VERSION ""

NS_ :

BS_:

BU_: BKU KVU
VAL_TABLE_ kvu_Workmodes 2 "Driver control" 1 "Local control from VMU commands" 0 "Controlled from BKU" ;
VAL_TABLE_ bku_lightsTurnMode 3 "Alarm" 2 "Right" 1 "Left" 0 "Disabled" ;
VAL_TABLE_ kvu_errorCode_priority 1 "critical" 0 "warning" ;
VAL_TABLE_ kvu_errorCode_source 17 "Power_management" 16 "Motor_drive" 15 "Voltage_monitoring" 14 "Suspension" 13 "Hydraulic_brakes" 12 "Charging" 11 "IO_lib_errors" 10 "Discrete_input" 9 "ABS" 8 "System" 7 "Parking_brake" 6 "Steering_rear" 5 "Steering_front" 4 "J1939" 3 "EEPROM" 2 "Lights" 1 "Canopen" 0 "Undefined" ;

BO_ 2566885541 BKU_resetErrors: 8 BKU
 SG_ bku_resetErrors_bits : 0|40@1+ (1,0) [0|1099511627775] ""  KVU

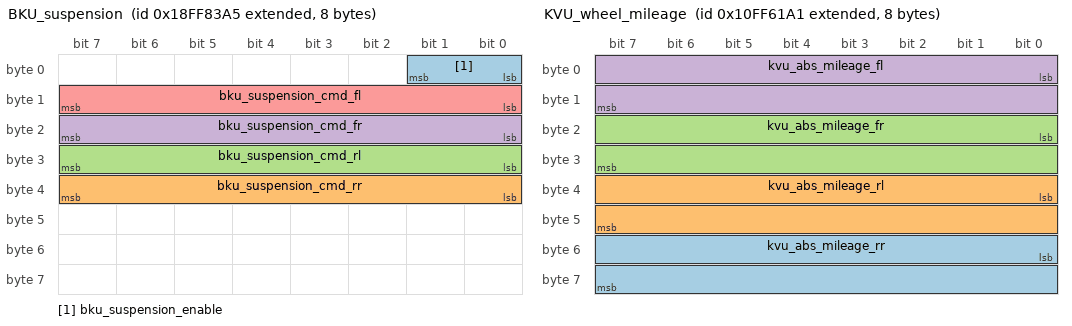
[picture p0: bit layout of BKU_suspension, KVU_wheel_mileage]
BO_ 2566882213 BKU_suspension: 8 BKU
 SG_ bku_suspension_enable : 0|2@1+ (1,0) [0|3] ""  KVU
 SG_ bku_suspension_cmd_rr : 32|8@1+ (2,-250) [-250|250] "mm"  KVU
 SG_ bku_suspension_cmd_rl : 24|8@1+ (2,-250) [-250|250] "mm"  KVU
 SG_ bku_suspension_cmd_fr : 16|8@1+ (2,-250) [-250|250] "mm"  KVU
 SG_ bku_suspension_cmd_fl : 8|8@1+ (2,-250) [-250|250] "mm"  KVU

BO_ 2432655777 KVU_wheel_mileage: 8 KVU
 SG_ kvu_abs_mileage_rr : 48|16@1+ (1,0) [0|32767] ""  BKU
 SG_ kvu_abs_mileage_rl : 32|16@1+ (1,0) [0|32767] ""  BKU
 SG_ kvu_abs_mileage_fr : 16|16@1+ (1,0) [0|32767] ""  BKU
 SG_ kvu_abs_mileage_fl : 0|16@1+ (1,0) [0|32767] ""  BKU

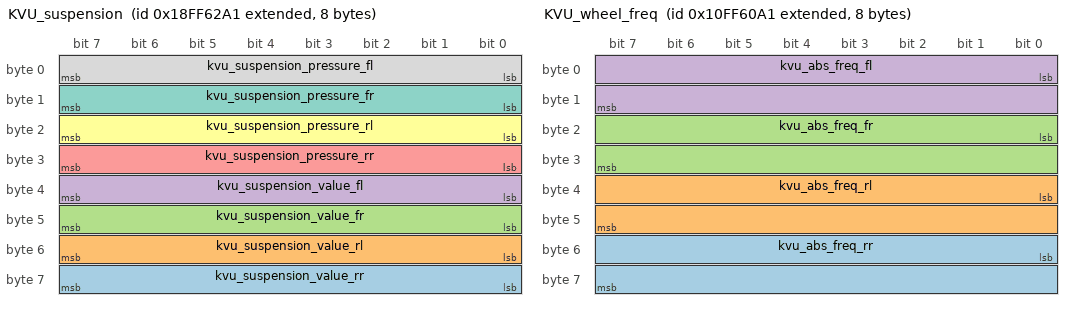
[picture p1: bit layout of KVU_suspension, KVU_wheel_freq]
BO_ 2566873761 KVU_suspension: 8 KVU
 SG_ kvu_suspension_value_rr : 56|8@1+ (2,-250) [-250|260] "mm"  BKU
 SG_ kvu_suspension_value_rl : 48|8@1+ (2,-250) [-250|260] "mm"  BKU
 SG_ kvu_suspension_value_fr : 40|8@1+ (2,-250) [-250|260] "mm"  BKU
 SG_ kvu_suspension_value_fl : 32|8@1+ (2,-250) [-250|260] "mm"  BKU
 SG_ kvu_suspension_pressure_rr : 24|8@1+ (0.1,0) [0|25] "atm"  BKU
 SG_ kvu_suspension_pressure_rl : 16|8@1+ (0.1,0) [0|25] "atm"  BKU
 SG_ kvu_suspension_pressure_fr : 8|8@1+ (0.1,0) [0|25] "atm"  BKU
 SG_ kvu_suspension_pressure_fl : 0|8@1+ (0.1,0) [0|25] "atm"  BKU

BO_ 2432655521 KVU_wheel_freq: 8 KVU
 SG_ kvu_abs_freq_rr : 48|16@1+ (0.002,-50) [-50|81.07] "Hz"  BKU
 SG_ kvu_abs_freq_rl : 32|16@1+ (0.002,-50) [-50|81.07] "Hz"  BKU
 SG_ kvu_abs_freq_fr : 16|16@1+ (0.002,-50) [-50|81.07] "Hz"  BKU
 SG_ kvu_abs_freq_fl : 0|16@1+ (0.002,-50) [-50|81.07] "Hz"  BKU

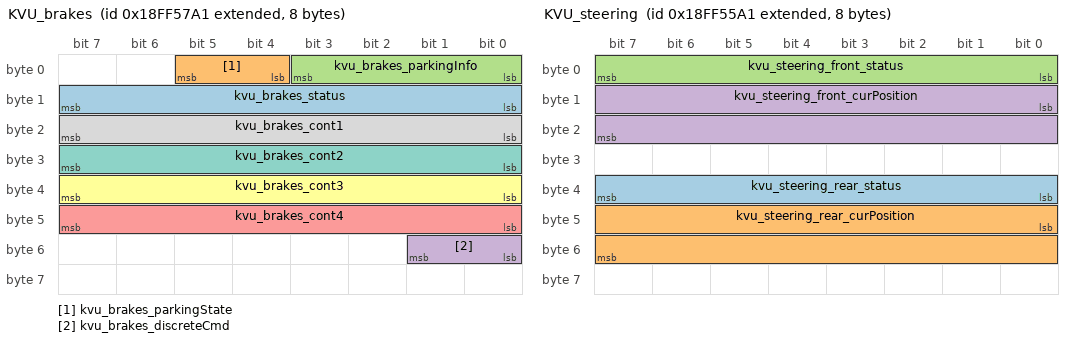
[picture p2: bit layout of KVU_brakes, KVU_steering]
BO_ 2566870945 KVU_brakes: 8 KVU
 SG_ kvu_brakes_status : 8|8@1+ (1,0) [0|0] ""  BKU
 SG_ kvu_brakes_parkingState : 4|2@1+ (1,0) [0|3] ""  BKU
 SG_ kvu_brakes_parkingInfo : 0|4@1+ (1,0) [0|15] ""  BKU
 SG_ kvu_brakes_discreteCmd : 48|2@1+ (1,0) [0|3] ""  BKU
 SG_ kvu_brakes_cont4 : 40|8@1+ (1,0) [0|255] "%"  BKU
 SG_ kvu_brakes_cont3 : 32|8@1+ (1,0) [0|255] "%"  BKU
 SG_ kvu_brakes_cont2 : 24|8@1+ (1,0) [0|255] "%"  BKU
 SG_ kvu_brakes_cont1 : 16|8@1+ (1,0) [0|255] "%"  BKU

BO_ 2566870433 KVU_steering: 8 KVU
 SG_ kvu_steering_rear_status : 32|8@1+ (1,0) [0|255] ""  BKU
 SG_ kvu_steering_rear_curPosition : 40|16@1+ (1,-30000) [-30000|35535] ""  BKU
 SG_ kvu_steering_front_status : 0|8@1+ (1,0) [0|255] ""  BKU
 SG_ kvu_steering_front_curPosition : 8|16@1+ (1,-30000) [-30000|35535] ""  BKU

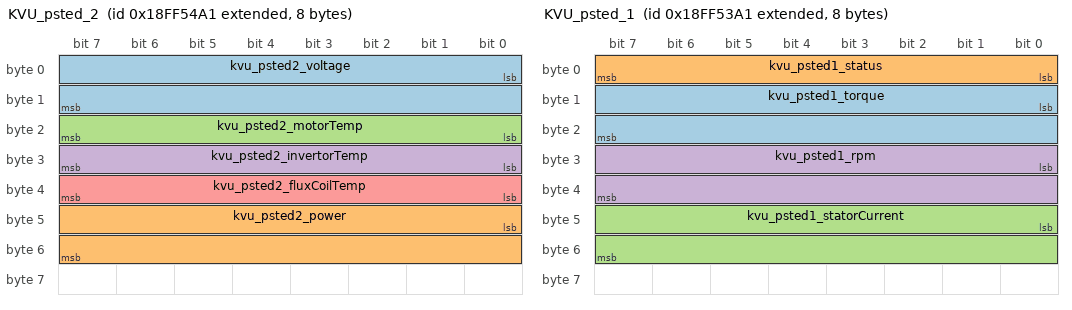
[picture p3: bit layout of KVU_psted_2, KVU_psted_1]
BO_ 2566870177 KVU_psted_2: 8 KVU
 SG_ kvu_psted2_voltage : 0|16@1+ (0.1,0) [0|6553.5] "V"  BKU
 SG_ kvu_psted2_power : 40|16@1+ (0.1,-2000) [-2000|4553.5] "kW"  BKU
 SG_ kvu_psted2_motorTemp : 16|8@1+ (1,-40) [-40|210] "°C"  BKU
 SG_ kvu_psted2_invertorTemp : 24|8@1+ (1,-40) [-40|210] "°C"  BKU
 SG_ kvu_psted2_fluxCoilTemp : 32|8@1+ (1,-40) [-40|210] "°C"  BKU

BO_ 2566869921 KVU_psted_1: 8 KVU
 SG_ kvu_psted1_torque : 8|16@1+ (0.01,-100) [-100|555.35] "%"  BKU
 SG_ kvu_psted1_status : 0|8@1+ (1,0) [0|255] ""  BKU
 SG_ kvu_psted1_statorCurrent : 40|16@1+ (0.1,-2000) [-2000|4553.5] "A"  BKU
 SG_ kvu_psted1_rpm : 24|16@1+ (0.25,-8000) [-8000|8383.75] "rpm"  BKU

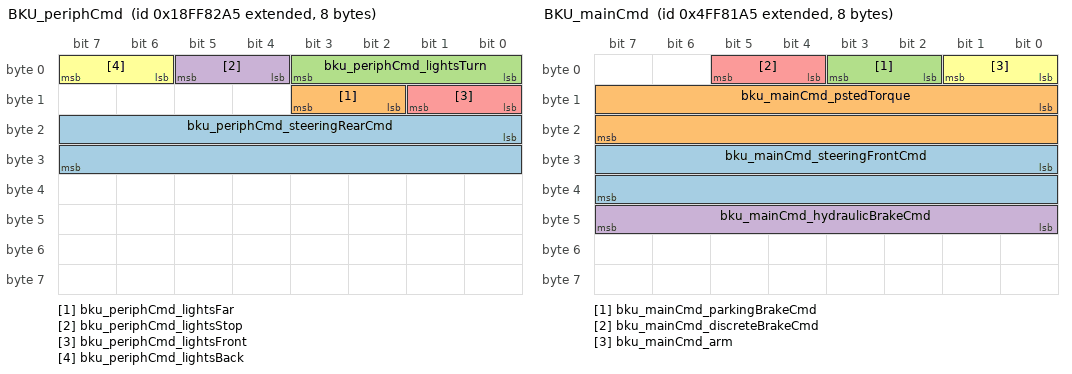
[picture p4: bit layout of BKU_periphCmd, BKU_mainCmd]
BO_ 2566881957 BKU_periphCmd: 8 BKU
 SG_ bku_periphCmd_steeringRearCmd : 16|16@1+ (0.01,-100) [-100|100] "%"  KVU
 SG_ bku_periphCmd_lightsFar : 10|2@1+ (1,0) [0|3] ""  KVU
 SG_ bku_periphCmd_lightsTurn : 0|4@1+ (1,0) [0|15] ""  KVU
 SG_ bku_periphCmd_lightsStop : 4|2@1+ (1,0) [0|3] ""  KVU
 SG_ bku_periphCmd_lightsFront : 8|2@1+ (1,0) [0|3] ""  KVU
 SG_ bku_periphCmd_lightsBack : 6|2@1+ (1,0) [0|3] ""  KVU

BO_ 2231337381 BKU_mainCmd: 8 BKU
 SG_ bku_mainCmd_steeringFrontCmd : 24|16@1+ (0.01,-100) [-100|100] "%"  KVU
 SG_ bku_mainCmd_pstedTorque : 8|16@1+ (0.01,-100) [-100|100] "%"  KVU
 SG_ bku_mainCmd_parkingBrakeCmd : 2|2@1+ (1,0) [0|3] ""  KVU
 SG_ bku_mainCmd_hydraulicBrakeCmd : 40|8@1+ (0.4,0) [0|100] "%"  KVU
 SG_ bku_mainCmd_discreteBrakeCmd : 4|2@1+ (1,0) [0|3] ""  KVU
 SG_ bku_mainCmd_arm : 0|2@1+ (1,0) [0|3] ""  KVU

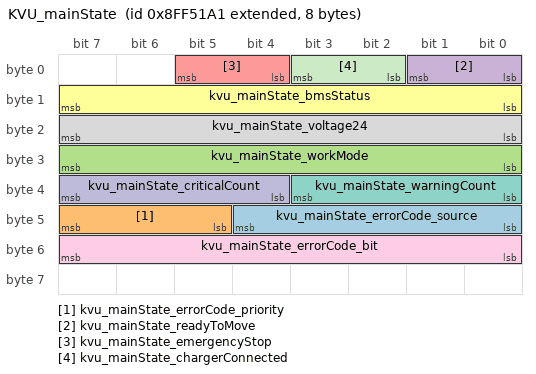
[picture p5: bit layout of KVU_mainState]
BO_ 2298433953 KVU_mainState: 8 KVU
 SG_ kvu_mainState_errorCode_source : 40|5@1+ (1,0) [0|31] ""  BKU
 SG_ kvu_mainState_errorCode_priority : 45|3@1+ (1,0) [0|7] ""  BKU
 SG_ kvu_mainState_workMode : 24|8@1+ (1,0) [0|255] ""  BKU
 SG_ kvu_mainState_readyToMove : 0|2@1+ (1,0) [0|3] ""  BKU
 SG_ kvu_mainState_emergencyStop : 4|2@1+ (1,0) [0|3] ""  BKU
 SG_ kvu_mainState_bmsStatus : 8|8@1+ (1,0) [0|255] ""  BKU
 SG_ kvu_mainState_warningCount : 32|4@1+ (1,0) [0|15] ""  BKU
 SG_ kvu_mainState_voltage24 : 16|8@1+ (0.1,10) [10|34] "V"  BKU
 SG_ kvu_mainState_errorCode_bit : 48|8@1+ (1,0) [0|255] ""  BKU
 SG_ kvu_mainState_criticalCount : 36|4@1+ (1,0) [0|15] ""  BKU
 SG_ kvu_mainState_chargerConnected : 2|2@1+ (1,0) [0|3] ""  BKU

CM_ SG_ 2566870945 kvu_brakes_status "Текущий статус контроллера системы плавного торможения";
CM_ SG_ 2566870945 kvu_brakes_parkingState "Состояние стояночного тормоза";
CM_ SG_ 2566870945 kvu_brakes_parkingInfo "Текущий статус блока управления электропривода стояночного тормоза ";
CM_ SG_ 2566870433 kvu_steering_rear_status "Текущий статус электропривода рулевой рейки задней оси ";
CM_ SG_ 2566870433 kvu_steering_rear_curPosition "Текущее положение электропривода рулевой рейки задней оси";
CM_ SG_ 2566870433 kvu_steering_front_status "Текущий статус электропривода рулевой рейки передней оси ";
CM_ SG_ 2566870433 kvu_steering_front_curPosition "Текущее положение электропривода рулевой рейки передней оси";
CM_ SG_ 2566870177 kvu_psted2_voltage "Напряжение на звене постоянного тока ПСТЭД";
CM_ SG_ 2566870177 kvu_psted2_power "Мощность тягового двигателя";
CM_ SG_ 2566870177 kvu_psted2_motorTemp "Температура тягового двигателя";
CM_ SG_ 2566870177 kvu_psted2_invertorTemp "Температура силового преобразователя тягового двигателя";
CM_ SG_ 2566870177 kvu_psted2_fluxCoilTemp "Температура обмотки возбуждения тягового двигателя,";
CM_ SG_ 2566869921 kvu_psted1_torque "Текущее значение момента, развиваемого двигателем";
CM_ SG_ 2566869921 kvu_psted1_status "Текущий статус ПСТЭД";
CM_ SG_ 2566869921 kvu_psted1_statorCurrent "Ток статора двигателя";
CM_ SG_ 2566869921 kvu_psted1_rpm "Текущая частота вращения двигателя";
CM_ SG_ 2298433953 kvu_mainState_workMode "Режим работы КВУ";
CM_ SG_ 2298433953 kvu_mainState_emergencyStop "Аварийный останов";
CM_ SG_ 2298433953 kvu_mainState_chargerConnected "Charger is connected to the vehicle";
BA_DEF_ SG_  "SigType" ENUM  "Default","Range","RangeSigned","ASCII","Discrete","Control","ReferencePGN","DTC","StringDelimiter","StringLength","StringLengthControl","MessageCounter","MessageChecksum";
BA_DEF_ SG_  "GenSigEVName" STRING ;
BA_DEF_ SG_  "GenSigILSupport" ENUM  "No","Yes";
BA_DEF_ SG_  "GenSigSendType" ENUM  "Cyclic","OnWrite","OnWriteWithRepetition","OnChange","OnChangeWithRepetition","IfActive","IfActiveWithRepetition","NoSigSendType";
BA_DEF_ SG_  "GenSigStartValue" INT 0 2147483647;
BA_DEF_ BO_  "GenMsgILSupport" ENUM  "No","Yes";
BA_DEF_ BU_  "NmStationAddress" INT 0 255;
BA_DEF_ BO_  "GenMsgSendType" ENUM  "cyclic","NotUsed","IfActive","NotUsed","NotUsed","NotUsed","NotUsed","NotUsed","noMsgSendType";
BA_DEF_ BO_  "GenMsgRequestable" INT 0 1;
BA_DEF_  "DBName" STRING ;
BA_DEF_  "BusType" STRING ;
BA_DEF_  "ProtocolType" STRING ;
BA_DEF_ BO_  "VFrameFormat" ENUM  "StandardCAN","ExtendedCAN","reserved","J1939PG";
BA_DEF_DEF_  "SigType" "Default";
BA_DEF_DEF_  "GenSigEVName" "Env@Nodename_@Signame";
BA_DEF_DEF_  "GenSigILSupport" "Yes";
BA_DEF_DEF_  "GenSigSendType" "NoSigSendType";
BA_DEF_DEF_  "GenSigStartValue" 0;
BA_DEF_DEF_  "GenMsgILSupport" "Yes";
BA_DEF_DEF_  "NmStationAddress" 254;
BA_DEF_DEF_  "GenMsgSendType" "noMsgSendType";
BA_DEF_DEF_  "GenMsgRequestable" 1;
BA_DEF_DEF_  "DBName" "";
BA_DEF_DEF_  "BusType" "CAN";
BA_DEF_DEF_  "ProtocolType" "J1939";
BA_DEF_DEF_  "VFrameFormat" "J1939PG";
BA_ "DBName" "N1_CAN2";
BA_ "NmStationAddress" BU_ BKU 165;
BA_ "NmStationAddress" BU_ KVU 161;
BA_ "GenSigStartValue" SG_ 2566882213 bku_suspension_cmd_rr 125;
BA_ "GenSigStartValue" SG_ 2566882213 bku_suspension_cmd_rl 125;
BA_ "GenSigStartValue" SG_ 2566882213 bku_suspension_cmd_fr 125;
BA_ "GenSigStartValue" SG_ 2566882213 bku_suspension_cmd_fl 125;
BA_ "GenSigStartValue" SG_ 2566873761 kvu_suspension_value_rr 125;
BA_ "GenSigStartValue" SG_ 2566873761 kvu_suspension_value_rl 125;
BA_ "GenSigStartValue" SG_ 2566873761 kvu_suspension_value_fr 125;
BA_ "GenSigStartValue" SG_ 2566873761 kvu_suspension_value_fl 125;
BA_ "GenSigStartValue" SG_ 2432655521 kvu_abs_freq_rr 25000;
BA_ "GenSigStartValue" SG_ 2432655521 kvu_abs_freq_rl 25000;
BA_ "GenSigStartValue" SG_ 2432655521 kvu_abs_freq_fr 25000;
BA_ "GenSigStartValue" SG_ 2432655521 kvu_abs_freq_fl 25000;
BA_ "GenSigStartValue" SG_ 2566870433 kvu_steering_rear_curPosition 30000;
BA_ "GenSigStartValue" SG_ 2566870433 kvu_steering_front_curPosition 30000;
BA_ "GenSigStartValue" SG_ 2566870177 kvu_psted2_power 20000;
BA_ "GenSigStartValue" SG_ 2566870177 kvu_psted2_motorTemp 40;
BA_ "GenSigStartValue" SG_ 2566870177 kvu_psted2_invertorTemp 40;
BA_ "GenSigStartValue" SG_ 2566870177 kvu_psted2_fluxCoilTemp 40;
BA_ "GenSigStartValue" SG_ 2566869921 kvu_psted1_torque 10000;
BA_ "GenSigStartValue" SG_ 2566869921 kvu_psted1_statorCurrent 20000;
BA_ "GenSigStartValue" SG_ 2566869921 kvu_psted1_rpm 32000;
BA_ "GenSigStartValue" SG_ 2566881957 bku_periphCmd_steeringRearCmd 10000;
BA_ "GenSigStartValue" SG_ 2231337381 bku_mainCmd_steeringFrontCmd 10000;
BA_ "GenSigStartValue" SG_ 2231337381 bku_mainCmd_pstedTorque 10000;
VAL_ 2566881957 bku_periphCmd_lightsTurn 3 "Alarm" 2 "Right" 1 "Left" 0 "Disabled" ;
VAL_ 2298433953 kvu_mainState_errorCode_source 17 "Power_management" 16 "Motor_drive" 15 "Voltage_monitoring" 14 "Suspension" 13 "Hydraulic_brakes" 12 "Charging" 11 "IO_lib_errors" 10 "Discrete_input" 9 "ABS" 8 "System" 7 "Parking_brake" 6 "Steering_rear" 5 "Steering_front" 4 "J1939" 3 "EEPROM" 2 "Lights" 1 "Canopen" 0 "Undefined" ;
VAL_ 2298433953 kvu_mainState_errorCode_priority 1 "critical" 0 "warning" ;
VAL_ 2298433953 kvu_mainState_workMode 2 "Driver control" 1 "Local control from VMU commands" 0 "Controlled from BKU" ;
